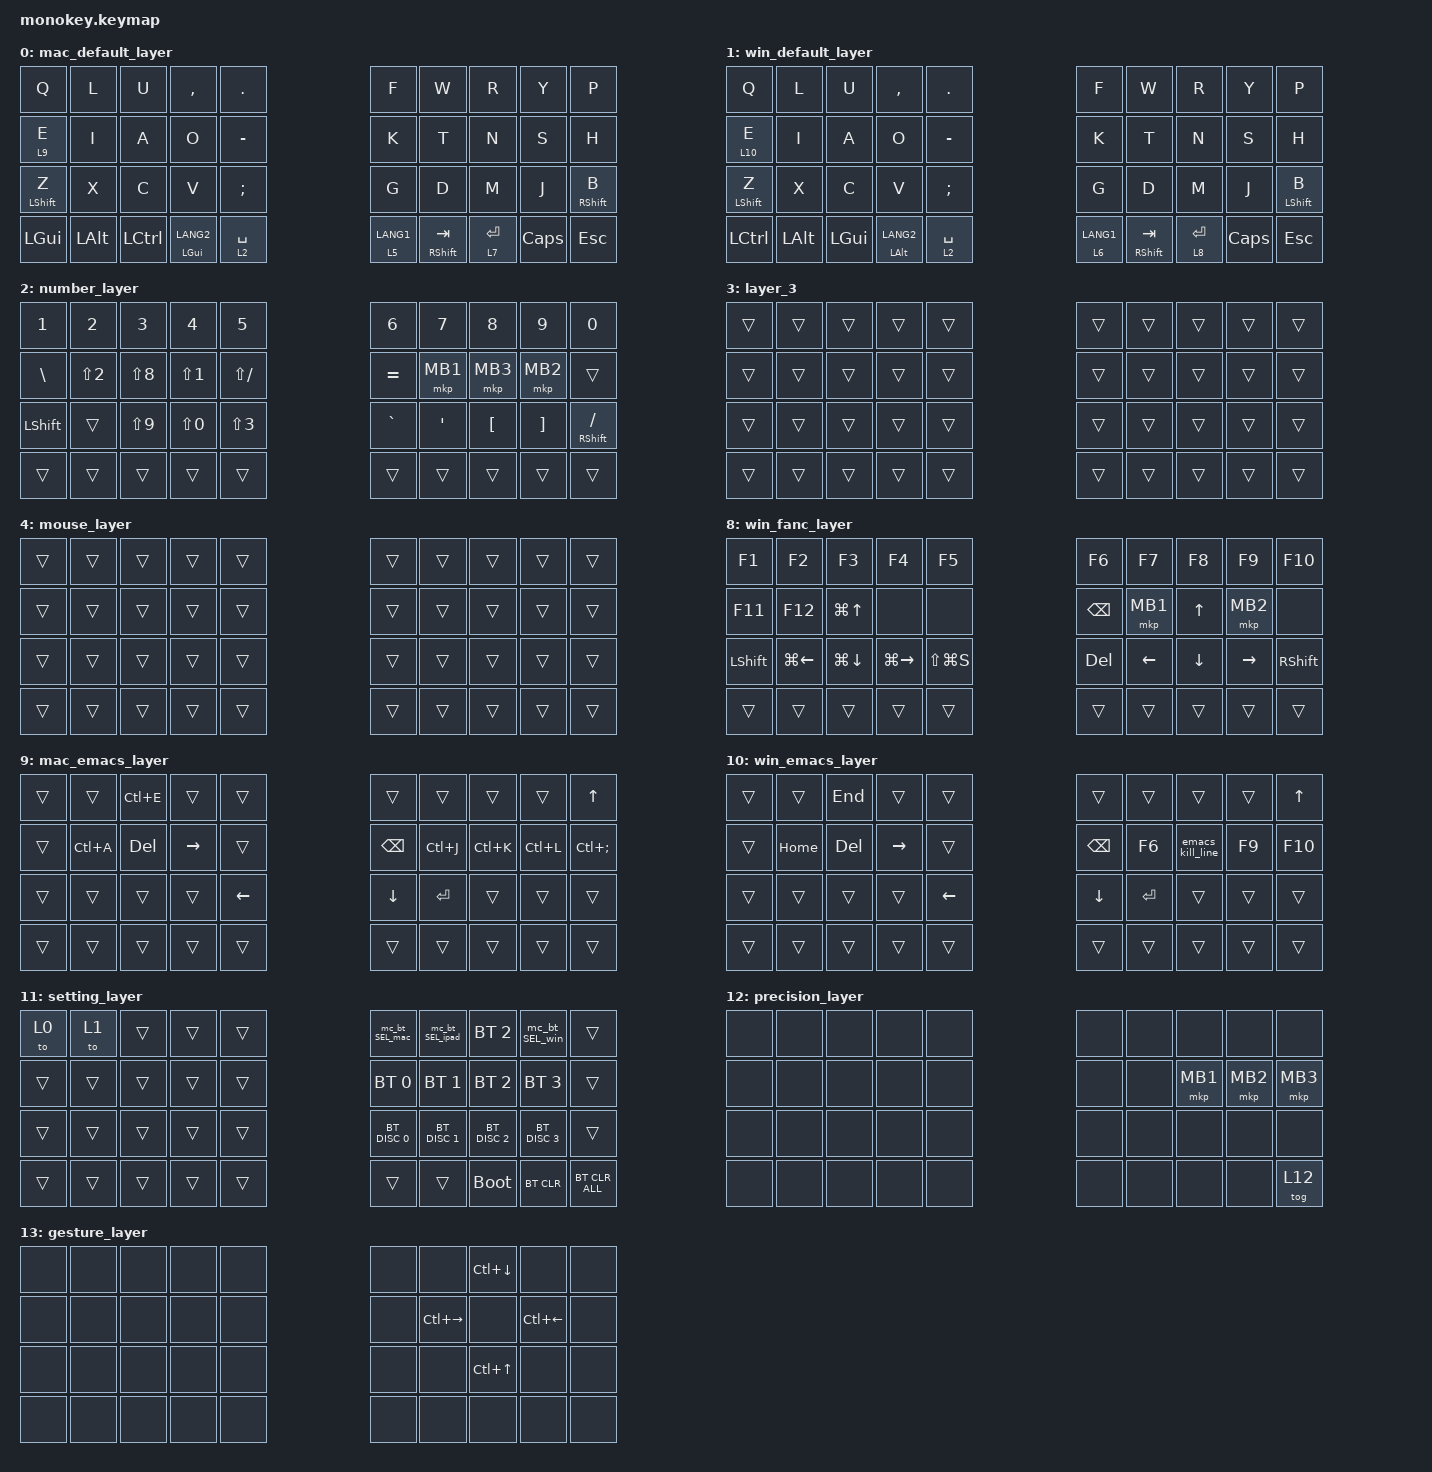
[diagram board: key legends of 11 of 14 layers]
/*
 * Copyright (c) 2024 Conductor Keyboard
 * Generated by Conductor Studio 2.0
 */

#include <behaviors.dtsi>
#include <dt-bindings/zmk/keys.h>
#include <dt-bindings/zmk/bt.h>
#include <dt-bindings/zmk/mouse.h>
#include <dt-bindings/zmk/pointing.h>

&mt {
    flavor = "tap-preferred";
    tapping-term-ms = <200>;
    quick-tap-ms = <200>;
};

&lt {
    tapping-term-ms = <200>;
    quick-tap-ms = <200>;
    flavor = "tap-preferred";
};

/ {
    behaviors {
        // マウスボタンを対象とするレイヤータップの定義
        lt_mouse: lt_mouse {
            compatible = "zmk,behavior-hold-tap";
            #binding-cells = <2>;
            flavor = "hold-preferred";
            tapping-term-ms = <200>;
            // 1つ目の引数にレイヤー(&mo)、2つ目にマウスクリック(&mkp)を指定可能にする
            bindings = <&mo>, <&mkp>;
        };

        /* Upstream v0.6.2 shift-only mod-tap behavior.
         * Defined for compatibility, but not used by the current keymap. */
        mt_shift: mt_shift {
            compatible = "zmk,behavior-hold-tap";
            #binding-cells = <2>;
            flavor = "tap-preferred";
            tapping-term-ms = <150>;
            quick-tap-ms = <250>;
            hold-while-undecided;
            bindings = <&kp>, <&kp>;
        };
    };

    combos {
        compatible = "zmk,combos";

        combo_scroll_MB3 {
            bindings = <&lt_mouse 5 MB3>;
            key-positions = <17 18>;
            timeout-ms = <25>;
        };

        combo_gesture {
            bindings = <&mo 13>;
            key-positions = <7 8>;
            timeout-ms = <50>;
        };

        combo_pair {
            bindings = <&bt BT_SEL 5>;
            key-positions = <0 10 20>;
            timeout-ms = <50>;
        };

        combo_boot {
            bindings = <&bootloader>;
            key-positions = <8 24 4>;
            timeout-ms = <50>;
        };

        combo_mb1 {
            timeout-ms = <25>;
            bindings = <&mkp MB1>;
            key-positions = <16 17>;
        };

        combo_mb2 {
            timeout-ms = <25>;
            bindings = <&mkp MB2>;
            key-positions = <18 19>;
        };
    };

    macros {
        mc_bt_SEL_mac: mc_bt_SEL_mac {
            compatible = "zmk,behavior-macro";
            #binding-cells = <0>;
            bindings
                = <&to 0>            // レイヤー0へ移行
                , <&macro_wait_time 200>    // 200ms 待機
                , <&bt BT_SEL 0>     // プロファイル0を選択して接続試行
                ;
        };

        mc_bt_SEL_ipad: mc_bt_SEL_ipad {
            compatible = "zmk,behavior-macro";
            #binding-cells = <0>;
            bindings
                = <&to 0>            // レイヤー0へ移行
                , <&macro_wait_time 200>    // 200ms 待機
                , <&bt BT_SEL 1>     // プロファイル1を選択して接続試行
                ;
        };

        mc_bt_SEL_win: mc_bt_SEL_win {
            compatible = "zmk,behavior-macro";
            #binding-cells = <0>;
            bindings
                = <&to 1>            // レイヤー1へ移行
                , <&macro_wait_time 200>    // 200ms 待機
                , <&bt BT_SEL 3>     // プロファイル3を選択して接続試行
                ;
        };

        // Emacs風 C-k (行末まで切り取り)
        emacs_kill_line: emacs_kill_line {
            compatible = "zmk,behavior-macro";
            #binding-cells = <0>;
            wait-ms = <10>;
            tap-ms = <10>;
            bindings
                = <&macro_press &kp LSHFT>
                , <&macro_tap &kp END>
                , <&macro_release &kp LSHFT>
                , <&macro_wait_time 20> // 切り取り前に少し待機（安定用）
                , <&macro_press &kp LCTRL>
                , <&macro_tap &kp X>
                , <&macro_release &kp LCTRL>
                ;
        };
    };

    keymap {
        compatible = "zmk,keymap";

        mac_default_layer {
            bindings = <
                &kp Q             &kp L         &kp U             &kp COMMA           &kp DOT                                        &kp F      &kp W  &kp R  &kp Y     &kp P
                &lt 9 E           &kp I         &kp A             &kp O               &kp MINUS                                      &kp K      &kp T  &kp N  &kp S     &kp H
                &mt LEFT_SHIFT Z  &kp X         &kp C             &kp V               &kp SEMI                                       &kp G      &kp D  &kp M  &kp J     &mt RIGHT_SHIFT B
                &kp LGUI          &kp LEFT_ALT  &kp LEFT_CONTROL  &mt LEFT_GUI LANG2  &lt 2 SPACE  &lt 5 LANG1  &mt RIGHT_SHIFT TAB  &lt 7 RET                &kp CAPS  &kp ESC
            >;

            sensor-bindings = <&inc_dec_kp PG_UP PG_DN>;
        };

        win_default_layer {
            bindings = <
                &kp Q             &kp L         &kp U         &kp COMMA           &kp DOT                                        &kp F       &kp W  &kp R  &kp Y     &kp P
                &lt 10 E          &kp I         &kp A         &kp O               &kp MINUS                                      &kp K       &kp T  &kp N  &kp S     &kp H
                &mt LEFT_SHIFT Z  &kp X         &kp C         &kp V               &kp SEMI                                       &kp G       &kp D  &kp M  &kp J     &mt LEFT_SHIFT B
                &kp LEFT_CONTROL  &kp LEFT_ALT  &kp LEFT_GUI  &mt LEFT_ALT LANG2  &lt 2 SPACE  &lt 6 LANG1  &mt RIGHT_SHIFT TAB  &lt 8 RET                &kp CAPS  &kp ESC
            >;
        };

        number_layer {
            bindings = <
                &kp N1          &kp N2      &kp N3      &kp N4      &kp N5                        &kp N6     &kp N7    &kp N8    &kp N9    &kp N0
                &kp BACKSLASH   &kp LS(N2)  &kp LS(N8)  &kp LS(N1)  &kp LS(FSLH)                  &kp EQUAL  &mkp MB1  &mkp MB3  &mkp MB2  &trans
                &kp LEFT_SHIFT  &trans      &kp LS(N9)  &kp LS(N0)  &kp LS(N3)                    &kp GRAVE  &kp SQT   &kp LBKT  &kp RBKT  &mt RIGHT_SHIFT FSLH
                &trans          &trans      &trans      &trans      &trans        &trans  &trans  &trans                         &trans    &trans
            >;
        };

        layer_3 {
            bindings = <
                &trans  &trans  &trans  &trans  &trans                  &trans  &trans  &trans  &trans  &trans
                &trans  &trans  &trans  &trans  &trans                  &trans  &trans  &trans  &trans  &trans
                &trans  &trans  &trans  &trans  &trans                  &trans  &trans  &trans  &trans  &trans
                &trans  &trans  &trans  &trans  &trans  &trans  &trans  &trans                  &trans  &trans
            >;
        };

        mouse_layer {
            bindings = <
                &trans  &trans  &trans  &trans  &trans                  &trans  &trans  &trans  &trans  &trans
                &trans  &trans  &trans  &trans  &trans                  &trans  &trans  &trans  &trans  &trans
                &trans  &trans  &trans  &trans  &trans                  &trans  &trans  &trans  &trans  &trans
                &trans  &trans  &trans  &trans  &trans  &trans  &trans  &trans                  &trans  &trans
            >;
        };

        mac_scroll_layer {
            bindings = <
                &kp C_BRI_DEC   &kp C_BRI_INC  &none       &kp LG(MINUS)          &kp LS(LG(EQUAL))                     &mkp MB5              &none  &none              &none              &kp LA(LC(LG(UP)))
                &kp C_VOL_DN    &kp C_VOL_UP   &kp C_MUTE  &kp LA(LC(LG(RIGHT)))  &none                                 &mkp MB4              &none  &kp LA(LC(LG(N)))  &kp LA(LC(LG(L)))  &trans
                &kp LEFT_SHIFT  &none          &none       &none                  &kp LA(LC(LG(LEFT)))                  &kp LA(LC(LG(DOWN)))  &none  &kp LA(LC(LG(M)))  &none              &kp RIGHT_SHIFT
                &trans          &trans         &trans      &trans                 &mo 11                &trans  &trans  &trans                                       &trans             &trans
            >;
        };

        win_scroll_layer {
            bindings = <
                &kp C_BRI_DEC   &kp C_BRI_INC  &none       &kp LG(MINUS)          &kp LS(LG(EQUAL))                     &mkp MB5       &none         &none            &none              &kp LG(UP)
                &kp C_VOL_DN    &kp C_VOL_UP   &kp C_MUTE  &kp LG(RIGHT)          &none                                 &mkp MB4       &none         &kp LG(LS(LEFT)) &kp LA(LC(LG(L)))  &trans
                &kp LEFT_SHIFT  &none          &none       &none                  &kp LG(LEFT)                          &kp LG(DOWN)   &none         &kp LG(UP)       &none              &kp RIGHT_SHIFT
                &trans          &trans         &trans      &trans                 &mo 11                &trans  &trans  &trans                                       &trans             &trans
            >;
        };

        mac_fanc_layer {
            bindings = <
                &kp F1          &kp F2        &kp F3             &kp F4         &kp F5                          &kp F6    &kp F7    &kp F8    &kp F9     &kp F10
                &kp F11         &kp F12       &kp LC(F)          &none          &none                           &kp BSPC  &mkp MB1  &kp UP    &mkp MB2   &none
                &kp LEFT_SHIFT  &kp LC(LEFT)  &kp LA(LC(LG(N)))  &kp LC(RIGHT)  &kp LC(LS(LG(N4)))              &kp DEL   &kp LEFT  &kp DOWN  &kp RIGHT  &kp RIGHT_SHIFT
                &trans          &trans        &trans             &trans         &trans          &trans  &trans  &trans                        &trans     &trans
            >;
        };

        win_fanc_layer {
            bindings = <
                &kp F1          &kp F2        &kp F3        &kp F4         &kp F5                         &kp F6    &kp F7    &kp F8    &kp F9     &kp F10
                &kp F11         &kp F12       &kp LG(UP)    &none          &none                          &kp BSPC  &mkp MB1  &kp UP    &mkp MB2   &none
                &kp LEFT_SHIFT  &kp LG(LEFT)  &kp LG(DOWN)  &kp LG(RIGHT)  &kp LS(LG(S))                  &kp DEL   &kp LEFT  &kp DOWN  &kp RIGHT  &kp RIGHT_SHIFT
                &trans          &trans        &trans        &trans         &trans         &trans  &trans  &trans                        &trans     &trans
            >;
        };

        mac_emacs_layer {
            bindings = <
                &trans  &trans     &kp LC(E)    &trans     &trans                    &trans    &trans     &trans     &trans     &kp UP
                &trans  &kp LC(A)  &kp DEL      &kp RIGHT  &trans                    &kp BSPC  &kp LC(J)  &kp LC(K)  &kp LC(L)  &kp LC(SEMI)
                &trans  &trans     &trans       &trans     &kp LEFT                  &kp DOWN  &kp RET    &trans     &trans     &trans
                &trans  &trans     &trans       &trans     &trans    &trans  &trans  &trans                          &trans     &trans
            >;
        };

        win_emacs_layer {
            bindings = <
                &trans  &trans    &kp END  &trans     &trans                    &trans    &trans   &trans            &trans  &kp UP
                &trans  &kp HOME  &kp DEL  &kp RIGHT  &trans                    &kp BSPC  &kp F6   &emacs_kill_line  &kp F9  &kp F10
                &trans  &trans    &trans   &trans     &kp LEFT                  &kp DOWN  &kp RET  &trans            &trans  &trans
                &trans  &trans    &trans   &trans     &trans    &trans  &trans  &trans                               &trans  &trans
            >;
        };

        setting_layer {
            bindings = <
            &to 0   &to 1   &trans  &trans  &trans                  &mc_bt_SEL_mac   &mc_bt_SEL_ipad  &bt BT_SEL 2   &mc_bt_SEL_win  &trans
            &trans  &trans  &trans  &trans  &trans                  &bt BT_SEL 0     &bt BT_SEL 1     &bt BT_SEL 2   &bt BT_SEL 3    &trans
            &trans  &trans  &trans  &trans  &trans                  &bt BT_DISC 0    &bt BT_DISC 1    &bt BT_DISC 2  &bt BT_DISC 3   &trans
            &trans  &trans  &trans  &trans  &trans  &trans  &trans  &bootloader                                      &bt BT_CLR      &bt BT_CLR_ALL
            >;
        };
        /* PRECISION layer (id=12): when active, trackball movement is scaled
         * down for fine cursor control (drafting, detailed work). Toggle with
         * &tog 12. Default bindings mirror mouse_layer so MB1-3 are reachable
         * during precision use; other keys are intentionally NONE to prevent
         * accidental typing while focused on cursor work. */
        precision_layer {
            bindings = <
                &none  &none  &none  &none  &none                  &none  &none     &none     &none     &none
                &none  &none  &none  &none  &none                  &none  &none     &mkp MB1  &mkp MB2  &mkp MB3
                &none  &none  &none  &none  &none                  &none  &none     &none     &none     &none
                &none  &none  &none  &none  &none  &none  &none  &none                  &none     &tog 12
            >;
        };

        /* GESTURE layer (id=13): I/J/L/COMMA map to up/left/right/down gestures. */
        gesture_layer {
            bindings = <
                &none  &none  &none  &none  &none                  &none  &none          &kp LC(DOWN)  &none         &none
                &none  &none  &none  &none  &none                  &none  &kp LC(RIGHT)  &none         &kp LC(LEFT)  &none
                &none  &none  &none  &none  &none                  &none  &none          &kp LC(UP)    &none         &none
                &none  &none  &none  &none  &none  &none  &none  &none                               &none         &none
            >;
        };

    };
};
